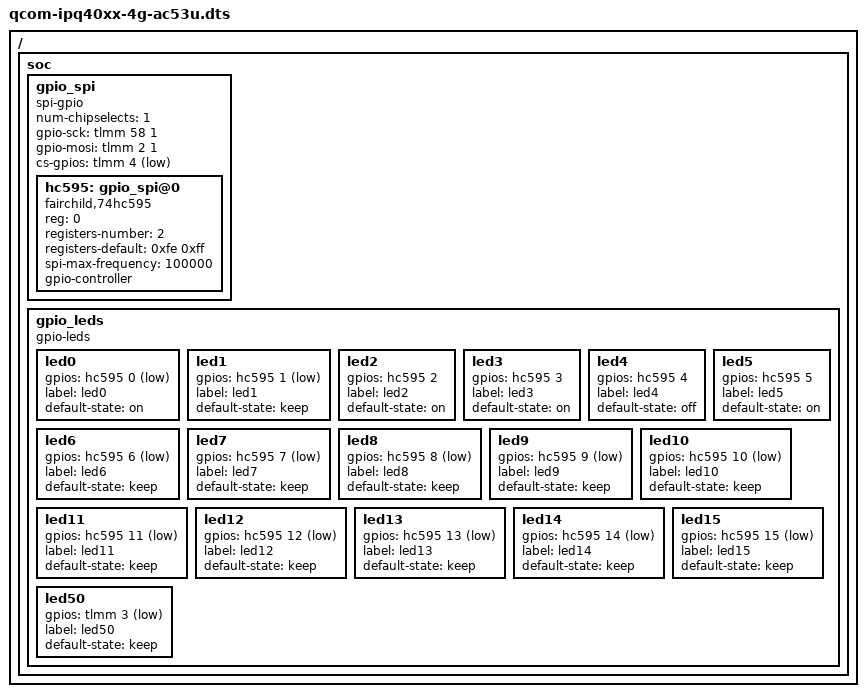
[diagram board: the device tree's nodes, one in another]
/* Copyright (c) 2015, The Linux Foundation. All rights reserved.
 *
 * Permission to use, copy, modify, and/or distribute this software for any
 * purpose with or without fee is hereby granted, provided that the above
 * copyright notice and this permission notice appear in all copies.
 *
 * THE SOFTWARE IS PROVIDED "AS IS" AND THE AUTHOR DISCLAIMS ALL WARRANTIES
 * WITH REGARD TO THIS SOFTWARE INCLUDING ALL IMPLIED WARRANTIES OF
 * MERCHANTABILITY AND FITNESS. IN NO EVENT SHALL THE AUTHOR BE LIABLE FOR
 * ANY SPECIAL, DIRECT, INDIRECT, OR CONSEQUENTIAL DAMAGES OR ANY DAMAGES
 * WHATSOEVER RESULTING FROM LOSS OF USE, DATA OR PROFITS, WHETHER IN AN
 * ACTION OF CONTRACT, NEGLIGENCE OR OTHER TORTIOUS ACTION, ARISING OUT OF
 * OR IN CONNECTION WITH THE USE OR PERFORMANCE OF THIS SOFTWARE.
 *
 */

#include "qcom-ipq40xx-ap.dk01.1-c2.dts"

/ {
	soc {
		gpio_spi {
			compatible = "spi-gpio";
			#address-cells = <0x1>;
			ranges;

			num-chipselects = <1>;
			gpio-sck = <&tlmm 58 1>;
			gpio-mosi = <&tlmm 2 1>;
			cs-gpios = <&tlmm 4 1>;

			hc595: gpio_spi@0 {
				compatible = "fairchild,74hc595";
				reg = <0>;
				registers-number = <2>;
				registers-default = /bits/ 8 <0xfe 0xff>;
				spi-max-frequency = <100000>;
				gpio-controller;
				#gpio-cells = <2>;
			};
		};

		gpio_leds {
			compatible = "gpio-leds";

			led0 {
				gpios = <&hc595 0 GPIO_ACTIVE_LOW>;
				label = "led0";	/* power:green:led */
				default-state = "on";
			};

			led1 {
				gpios = <&hc595 1 GPIO_ACTIVE_LOW>;
				label = "led1";	/* reset:red:led */
				default-state = "keep";
			};

			led2 {
				gpios = <&hc595 2 GPIO_ACTIVE_HIGH>;
				label = "led2";	/* w_disable */
				default-state = "on";
			};

			led3 {
				gpios = <&hc595 3 GPIO_ACTIVE_HIGH>;
				label = "led3";	/* pmd_resin_n */
				default-state = "on";
			};

			led4 {
				gpios = <&hc595 4 GPIO_ACTIVE_HIGH>;
				label = "led4";	/* lte_power_en */
				default-state = "off";
			};

			led5 {
				gpios = <&hc595 5 GPIO_ACTIVE_HIGH>;
				label = "led5";	/* usb_en */
				default-state = "on";
			};

			led6 {
				gpios = <&hc595 6 GPIO_ACTIVE_LOW>;
				label = "led6";	/* tp28 */
				default-state = "keep";
			};

			led7 {
				gpios = <&hc595 7 GPIO_ACTIVE_LOW>;
				label = "led7";	/* tp27 */
				default-state = "keep";
			};

			led8 {
				gpios = <&hc595 8 GPIO_ACTIVE_LOW>;
				label = "led8";	/* wifi:green:2_4g */
				default-state = "keep";
			};

			led9 {
				gpios = <&hc595 9 GPIO_ACTIVE_LOW>;
				label = "led9";	/* wifi:green:5g */
				default-state = "keep";
			};

			led10 {
				gpios = <&hc595 10 GPIO_ACTIVE_LOW>;
				label = "led10";	/* wps:green */
				default-state = "keep";
			};

			led11 {
				gpios = <&hc595 11 GPIO_ACTIVE_LOW>;
				label = "led11";	/* voip:green */
				default-state = "keep";
			};

			led12 {
				gpios = <&hc595 12 GPIO_ACTIVE_LOW>;
				label = "led12";	/* lte:green:s1 */
				default-state = "keep";
			};

			led13 {
				gpios = <&hc595 13 GPIO_ACTIVE_LOW>;
				label = "led13";	/* lte:green:s2 */
				default-state = "keep";
			};

			led14 {
				gpios = <&hc595 14 GPIO_ACTIVE_LOW>;
				label = "led14";	/* lte:green:s3 */
				default-state = "keep";
			};

			led15 {
				gpios = <&hc595 15 GPIO_ACTIVE_LOW>;
				label = "led15";	/* lte:green:s4 */
				default-state = "keep";
			};

			led50 {
				gpios = <&tlmm 3 GPIO_ACTIVE_LOW>;
				label = "led50";	/* lte_off_signal */
				default-state = "keep";
			};
		};
	};
};
